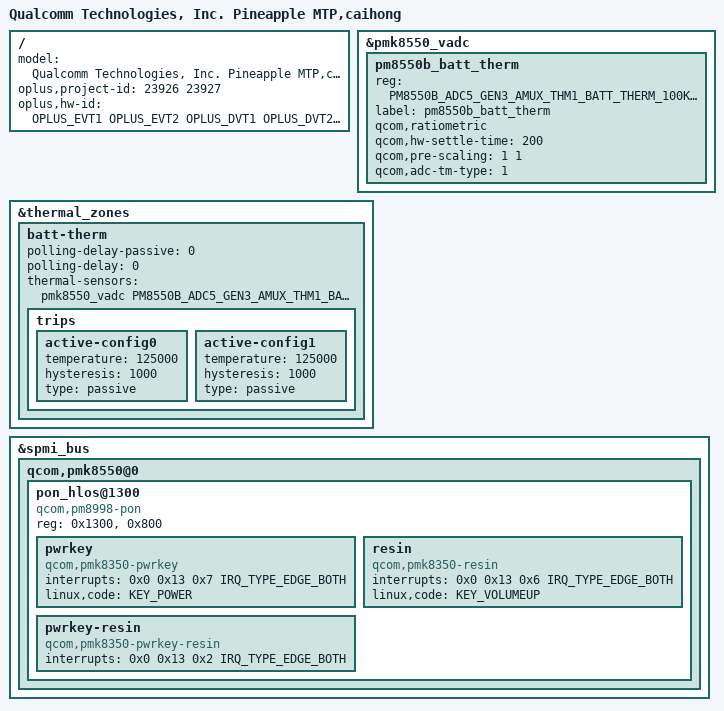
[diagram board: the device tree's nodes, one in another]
/dts-v1/;
/plugin/;
#include <dt-bindings/oplus/hw-id.h>
#include "../qcom/pineapple-mtp-overlay.dts"
#include "pineapple_overlay_common.dtsi"
#include "caihong_overlay_common.dtsi"
#include "oplus_chg/oplus-chg-23926.dtsi"
#include "oplus_misc/oplus-misc-23926.dtsi"
#include "tp/caihong-oplus-tp-23926.dtsi"
#include "tp/caihong-oplus-tp-23926_firmware.dtsi"
#include "sensor/caihong-sensor-23926.dtsi"
#include "oplus_pogo_kb/caihong-oplus-pogopin-kb-23926.dtsi"

/ {
    model = "Qualcomm Technologies, Inc. Pineapple MTP,caihong";

    oplus,project-id = <23926 23927>;
    oplus,hw-id = <OPLUS_EVT1 OPLUS_EVT2 OPLUS_DVT1 OPLUS_DVT2 OPLUS_PVT1 OPLUS_MP1 OPLUS_MP2 OPLUS_MP3>;
};

&pmk8550_vadc {
	pm8550b_batt_therm {
		reg = <PM8550B_ADC5_GEN3_AMUX_THM1_BATT_THERM_100K_PU>;
		label = "pm8550b_batt_therm";
		qcom,ratiometric;
		qcom,hw-settle-time = <200>;
		qcom,pre-scaling = <1 1>;
		qcom,adc-tm-type = <1>;
	};
};

&thermal_zones {
	batt-therm {
		polling-delay-passive = <0>;
		polling-delay = <0>;
		thermal-sensors = <&pmk8550_vadc PM8550B_ADC5_GEN3_AMUX_THM1_BATT_THERM_100K_PU>;
		trips {
			active-config0 {
				temperature = <125000>;
				hysteresis = <1000>;
				type = "passive";
			};

			active-config1 {
				temperature = <125000>;
				hysteresis = <1000>;
				type = "passive";
			};
		};
	};
};

&spmi_bus {
	 qcom,pmk8550@0 {
		pon_hlos@1300 {
			compatible = "qcom,pm8998-pon";
			reg = <0x1300>, <0x800>;
			reg-names = "pon_hlos", "pon_pbs";

			pwrkey {
				compatible = "qcom,pmk8350-pwrkey";
				interrupts = <0x0 0x13 0x7 IRQ_TYPE_EDGE_BOTH>;
				linux,code = <KEY_POWER>;
			};

			resin {
				compatible = "qcom,pmk8350-resin";
				interrupts = <0x0 0x13 0x6 IRQ_TYPE_EDGE_BOTH>;
				linux,code = <KEY_VOLUMEUP>;
			};

			pwrkey-resin {
				compatible = "qcom,pmk8350-pwrkey-resin";
				interrupts = <0x0 0x13 0x2 IRQ_TYPE_EDGE_BOTH>;
			};
		};
	};
};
